# PIC32CX0525SG12144 register map
Vendor: Microchip Technology; Series: 0525SG12; File version: 0
CPU: CM4 r1p0, little endian, no MPU, no FPU, 3 interrupt priority bits, 172 interrupts
Registers are 32-bit, read-write, reset 0x0 unless marked. A register's access mark holds for its fields unless they carry their own. Offsets are from the block's base; [hi:lo] are bit positions.

## PHOT — This block monitors the PROCHOT# signal generated by the host processor. It is designed to detect single assertions and monitor cumulative PROCHOT active time.
Base 0x40003400
0x00 CUCNT — PROCHOT Cumulative Count Register
  [23:0] ACTIVE — This register contains the current filtered PROCHOT Active Counter value.
0x04 DC_CNT — PROCHOT Duty Cycle Count Register
  [23:0] CNT — The contents of the PROCHOT Cumulative Count Register is copied into this register when the PROCHOT Duty Cycle Period Register transitions from 1 to 0.
0x08 DC_PER — PROCHOT Duty Cycle Period Register
  [23:0] PER — This register defines the number of 100KHz periods required for a duty cycle measurement.
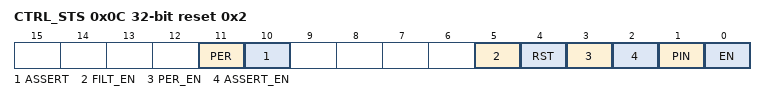
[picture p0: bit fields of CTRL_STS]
0x0C CTRL_STS reset 0x2 — PROCHOT Status/Control Register
  [11] PER — This sticky status bit is set to '1b' when the PROCHOT Period Counter transitions from '1b' to '0b.' (R/WC)
  [10] ASSERT — This bit is set when the PROCHOT Assertion Counter Register value is greater than or equal to the PROCHOT Assertion Counter Limit Register value. (R/WC)
  [5] FILT_EN — This bit determines whether a digital filter eliminates pulses on the PROCHOT# signal before PROCHOT# is sampled by the Assertion counter or the Active counter.
  [4] RST — Writing this self-clearing bit to one resets all the registers and logic in the PROCHOT Monitor block to its defined initial state.
  [3] PER_EN — This bit determines whether or not an interrupt will be generated when the PHOT_PERIOD bit is set.
  [2] ASSERT_EN — This bit determines whether or not an interrupt will be generated when the PHOT_ASSERT bit is set.
  [1] PIN — When PHOT_ENABLE is 1b, this bit reflects the state of the PROCHOT# Pin input.
  [0] EN — This bit enables the PROCHOT Monitor logic.
0x10 ASCNT — PROCHOT Assertion Counter Register
  [15:0] CNT — The PROCHOT Assertion Counter is a 16-bit up-counter that is clocked by the 100KHz and is gated and reset by the PROCHOT# input signal. This counter is used to measure a single PROCHOT assertion.
0x14 ASCLIM — PROCHOT Assertion Counter Register
  [15:0] CLIM — The PROCHOT Assertion Counter Limit register is compared to the 16-bit PROCHOT Assertion Counter.

## KMS — The Keyboard Scan Interface block provides a register interface to directly scan an external keyboard matrix of size up to 18x8.
Base 0x40009C00
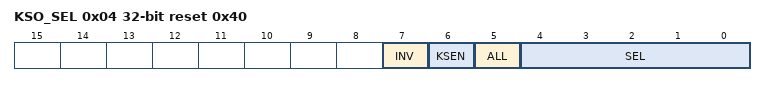
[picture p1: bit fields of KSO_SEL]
0x04 KSO_SEL reset 0x40 — KSO Select and control
  [7] INV — 0= KSO[x] driven low when selected, 1= KSO[x] driven high when selected.
  [6] KSEN — 0= Keyboard scan enabled, 1= Keyboard scan disabled. All KSO output buffers disabled.
  [5] ALL — 0=When key scan is enabled, KSO output controlled by the KSO_SELECT field. 1=KSO[x] driven high when selected.
  [4:0] SEL — This field selects a KSO line (00000b = KSO[0] etc.) for output according to the value off KSO_INVERT in this register.
0x08 KSI ro — [7:0] This field returns the current state of the KSI pins.
0x0C KSI_STS — [7:0] Each bit in this field is set on the falling edge of the corresponding KSI input pin. A KSI interrupt is generated when its corresponding status bit and interrupt enable bit are both set. KSI interrupts are logically ORed together to produce KSC_INT and KSC_INT_WAKE. Writing a '1' to a bit will clear it. Writing a '0' to a bit has no effect.
0x10 KSI_IEN — [7:0] Each bit in KSI_INT_EN enables interrupt generation due to highto-low transition on a KSI input. An interrupt is generated when the corresponding bits in KSI_STATUS and KSI_INT_EN are both set.
0x14 EXT_CTRL — [0:0] PREDRIVE_ENABLE enables the PREDRIVE mode to actively drive the KSO pins high for approximately 100ns before switching to open-drain operation. 0=Disable predrive on KSO pins. 1=Enable predrive on KSO pins.
